# AT32WB415xx_v2 register map
Vendor: Keil; Series: AT32WB415; File version: 1.0
CPU: CM4 r0p1, little endian, no MPU, FPU, 4 interrupt priority bits
Registers are 32-bit, read-write, reset 0x0 unless marked. A register's access mark holds for its fields unless they carry their own. Offsets are from the block's base; [hi:lo] are bit positions.

## SPI2 — Serial peripheral interface
Base 0x40003800
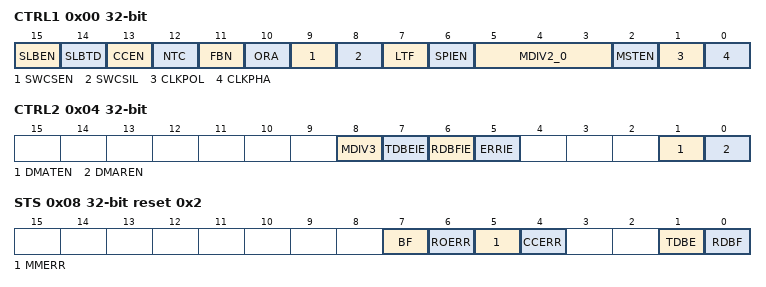
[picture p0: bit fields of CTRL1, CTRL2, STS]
0x00 CTRL1 — control register 1
  [15] SLBEN — Single line bidirectional half-duplex enable
  [14] SLBTD — Single line bidirectional half-duplex transmission direction
  [13] CCEN — CRC calculation enable
  [12] NTC — Next transmission CRC
  [11] FBN — frame bit num
  [10] ORA — Only receive active
  [9] SWCSEN — Software CS enable
  [8] SWCSIL — Software CS internal level
  [7] LTF — LSB transmit first
  [6] SPIEN — SPI enable
  [5:3] MDIV2_0 — Master clock frequency division bit2-0
  [2] MSTEN — Master enable
  [1] CLKPOL — Clock polarity
  [0] CLKPHA — Clock phase
0x04 CTRL2 — control register 2
  [8] MDIV3 — Master clock frequency division bit3
  [7] TDBEIE — Transmit data buffer empty interrupt enable
  [6] RDBFIE — Receive data buffer full interrupt enable
  [5] ERRIE — Error interrupt enable
  [1] DMATEN — DMA transmit enable
  [0] DMAREN — DMA receive enable
0x08 STS reset 0x2 — status register
  [7] BF ro — Busy flag
  [6] ROERR ro — Receiver overflow error
  [5] MMERR ro — Master mode error
  [4] CCERR — CRC calculation error
  [1] TDBE ro — Transmit data buffer empty
  [0] RDBF ro — Receive data buffer full
0x0C DT — data register
  [15:0] DT — Data value
0x10 CPOLY reset 0x7 — CRC polynomial register
  [15:0] CPOLY — CRC polynomial
0x14 RCRC ro — Receive CRC register
  [15:0] RCRC — Receive CRC
0x18 TCRC ro — Transmit CRC register
  [15:0] TCRC — Transmit CRC

## USART1 — Universal synchronous asynchronous receiver transmitter
Base 0x40013800
Same registers: USART2 0x40004400, USART3 0x40004800
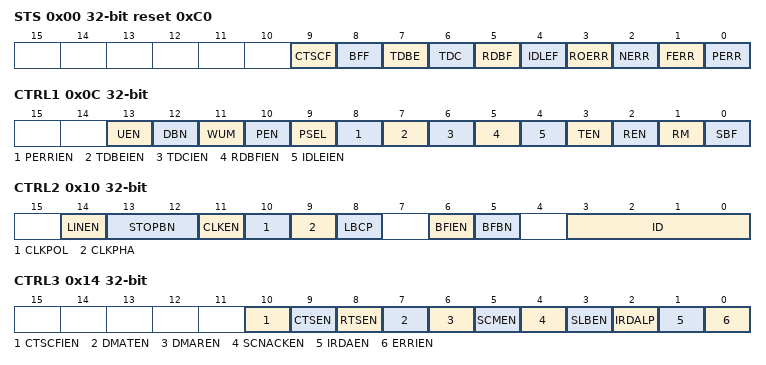
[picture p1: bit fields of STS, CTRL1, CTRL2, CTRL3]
0x00 STS reset 0xC0 — Status register
  [9] CTSCF — CTS change flag
  [8] BFF — Break frame flag
  [7] TDBE ro — Transmit data buffer empty
  [6] TDC — Transmit data complete
  [5] RDBF — Receive data buffer full
  [4] IDLEF ro — IDLE flag
  [3] ROERR ro — Receiver overflow error
  [2] NERR ro — Noise error
  [1] FERR ro — Framing error
  [0] PERR ro — Parity error
0x04 DT — Data register
  [8:0] DT — Data value
0x08 BAUDR — Baud rate register
  [15:0] DIV — Division
0x0C CTRL1 — Control register 1
  [13] UEN — USART enable
  [12] DBN — Data bit num
  [11] WUM — Wake up mode
  [10] PEN — Parity enable
  [9] PSEL — Parity selection
  [8] PERRIEN — PERR interrupt enable
  [7] TDBEIEN — TDBE interrupt enable
  [6] TDCIEN — TDC interrupt enable
  [5] RDBFIEN — RDBF interrupt enable
  [4] IDLEIEN — IDLE interrupt enable
  [3] TEN — Transmitter enable
  [2] REN — Receiver enable
  [1] RM — Receiver mute
  [0] SBF — Send break frame
0x10 CTRL2 — Control register 2
  [14] LINEN — LIN mode enable
  [13:12] STOPBN — STOP bit num
  [11] CLKEN — Clock enable
  [10] CLKPOL — Clock polarity
  [9] CLKPHA — Clock phase
  [8] LBCP — Last bit clock pulse
  [6] BFIEN — Break frame interrupt enable
  [5] BFBN — Break frame bit num
  [3:0] ID — USART identification
0x14 CTRL3 — Control register 3
  [10] CTSCFIEN — CTSCF interrupt enable
  [9] CTSEN — CTS enable
  [8] RTSEN — RTS enable
  [7] DMATEN — DMA transmitter enable
  [6] DMAREN — DMA receiver enable
  [5] SCMEN — Smartcard mode enable
  [4] SCNACKEN — Smartcard NACK enable
  [3] SLBEN — Single line bidirectional half-duplex enable
  [2] IRDALP — IrDA low-power mode
  [1] IRDAEN — IrDA enable
  [0] ERRIEN — Error interrupt enable
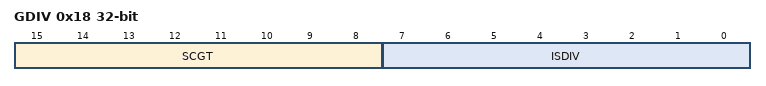
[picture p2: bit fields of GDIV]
0x18 GDIV — Guard time and division register
  [15:8] SCGT — Smart card guard time value
  [7:0] ISDIV — IrDA/smartcard division value

## CMP — Comparator
Base 0x40002400
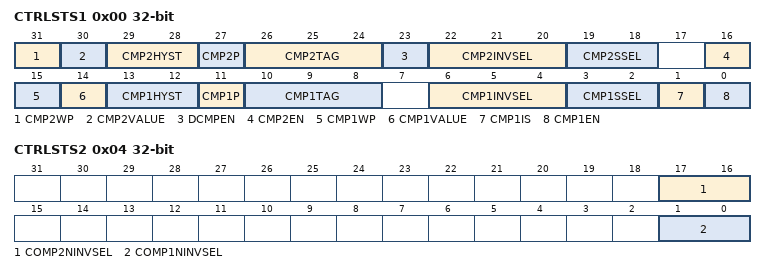
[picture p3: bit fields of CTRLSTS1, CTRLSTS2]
0x00 CTRLSTS1 — CMP control/status register1
  [31] CMP2WP — Comparator2 write protect
  [30] CMP2VALUE ro — Comparator2 output value
  [29:28] CMP2HYST — Comparator2 hysteresis
  [27] CMP2P — Comparator2 polarity
  [26:24] CMP2TAG — Comparator2 output target
  [23] DCMPEN — Double comparator mode enable
  [22:20] CMP2INVSEL — Comparator2 inverting selection
  [19:18] CMP2SSEL — Comparator2 speed selection
  [16] CMP2EN — Comparator2 enable bit
  [15] CMP1WP — Comparator1 write protect
  [14] CMP1VALUE ro — Comparator1 output value
  [13:12] CMP1HYST — Comparator1 hysteresis
  [11] CMP1P — Comparator1 polarity
  [10:8] CMP1TAG — Comparator1 output target
  [6:4] CMP1INVSEL — Comparator1 inverting selection
  [3:2] CMP1SSEL — Comparator1 speed selection
  [1] CMP1IS — Comparator1 input shift
  [0] CMP1EN — Comparator1 enable bit
0x04 CTRLSTS2 — CMP control/status register2
  [17:16] COMP2NINVSEL — Comparator2 non-inverting input selection
  [1:0] COMP1NINVSEL — Comparator1 non-inverting input selection

## Notices in the file
Copyright (C) 2012-2014 ARM Limited. All rights reserved.
Purpose: System Viewer Description (SVD) Example (Schema Version 1.1)
This is a description of a none-existent and incomplete device
for demonstration purposes only.
Redistribution and use in source and binary forms, with or without
modification, are permitted provided that the following conditions are met:
- Redistributions of source code must retain the above copyright
notice, this list of conditions and the following disclaimer.
- Redistributions in binary form must reproduce the above copyright
notice, this list of conditions and the following disclaimer in the
documentation and/or other materials provided with the distribution.
- Neither the name of ARM nor the names of its contributors may be used
to endorse or promote products derived from this software without
specific prior written permission.
THIS SOFTWARE IS PROVIDED BY THE COPYRIGHT HOLDERS AND CONTRIBUTORS "AS IS"
AND ANY EXPRESS OR IMPLIED WARRANTIES, INCLUDING, BUT NOT LIMITED TO, THE
IMPLIED WARRANTIES OF MERCHANTABILITY AND FITNESS FOR A PARTICULAR PURPOSE
ARE DISCLAIMED. IN NO EVENT SHALL COPYRIGHT HOLDERS AND CONTRIBUTORS BE
LIABLE FOR ANY DIRECT, INDIRECT, INCIDENTAL, SPECIAL, EXEMPLARY, OR
CONSEQUENTIAL DAMAGES (INCLUDING, BUT NOT LIMITED TO, PROCUREMENT OF
SUBSTITUTE GOODS OR SERVICES; LOSS OF USE, DATA, OR PROFITS; OR BUSINESS
INTERRUPTION) HOWEVER CAUSED AND ON ANY THEORY OF LIABILITY, WHETHER IN
CONTRACT, STRICT LIABILITY, OR TORT (INCLUDING NEGLIGENCE OR OTHERWISE)
ARISING IN ANY WAY OUT OF THE USE OF THIS SOFTWARE, EVEN IF ADVISED OF THE
POSSIBILITY OF SUCH DAMAGE.
